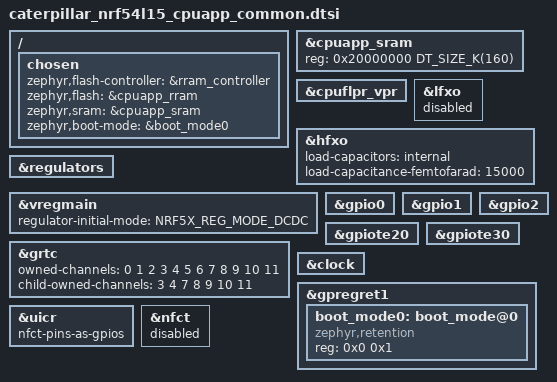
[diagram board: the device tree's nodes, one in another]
/*
 * Copyright (c) 2024 Nordic Semiconductor ASA
 * SPDX-License-Identifier: Apache-2.0
 */

#include "caterpillar_common.dtsi"

/ {
	chosen {
		zephyr,flash-controller = &rram_controller;
		zephyr,flash = &cpuapp_rram;
		zephyr,sram = &cpuapp_sram;
		zephyr,boot-mode = &boot_mode0;
	};

};

/* App SRAM shrinks to 160 KB — the FLPR owns the top 96 KB (the last
 * 1 KB of which is the IMU shared block, see common/imu_shared.h)
 */
&cpuapp_sram {
	status = "okay";
	reg = <0x20000000 DT_SIZE_K(160)>;
	ranges = <0x0 0x20000000 0x28000>;
};

/* FLPR coprocessor: firmware is EMBEDDED in the app image and launched
 * by src/flpr_launch.c (copy to SRAM 0x20028000 + VPR HAL start), so
 * app OTA updates carry it.  No execution-memory/source-memory here on
 * purpose — that would enable Zephyr's DT-based VPR launcher in every
 * image built from this devicetree (including MCUboot), and a second
 * launcher re-copying over the running coprocessor is fatal.
 */
&cpuflpr_vpr {
	status = "okay";
};

&lfxo {
	status = "disabled";
};

&hfxo {
	load-capacitors = "internal";
	load-capacitance-femtofarad = <15000>;
};

&regulators {
	status = "okay";
};

&vregmain {
	status = "okay";
	regulator-initial-mode = <NRF5X_REG_MODE_DCDC>;
};

&grtc {
	owned-channels = <0 1 2 3 4 5 6 7 8 9 10 11>;
	child-owned-channels = <3 4 7 8 9 10 11>;
	status = "okay";
};

&gpio0 {
	status = "okay";
};

&gpio1 {
	status = "okay";
};

&gpio2 {
	status = "okay";
};

/* gpiote20 must stay enabled for the app's gpio1 use (driver
 * requirement), but the app configures no pin interrupts on it — the
 * FLPR services the IMU DRDY edge (P1.04) through its own GPIOTE
 * interrupt group.
 */
&gpiote20 {
	status = "okay";
};

&gpiote30 {
	status = "okay";
};

&clock {
	status = "okay";
};

&gpregret1 {
	status = "okay";

	boot_mode0: boot_mode@0 {
		compatible = "zephyr,retention";
		status = "okay";
		reg = <0x0 0x1>;
	};
};

// Using NFC pins as i2c bus
&uicr {
    nfct-pins-as-gpios;
};

&nfct {
    status = "disabled";
};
